# ESP32-C5 register map
Vendor: ESPRESSIF SYSTEMS (SHANGHAI) CO., LTD.; Series: ESP32 C-Series; File version: 1
CPU: RV32IMAC r0p0, little endian, no MPU, no FPU, 0 interrupt priority bits
Address unit: 32 bits
Registers are 32-bit, read-write, reset 0x0 unless marked. A register's access mark holds for its fields unless they carry their own. Offsets are from the block's base; [hi:lo] are bit positions; {n}, {i} and the like mark numbered series.

## AHB_DMA — AHB_DMA Peripheral
Base 0x60080000
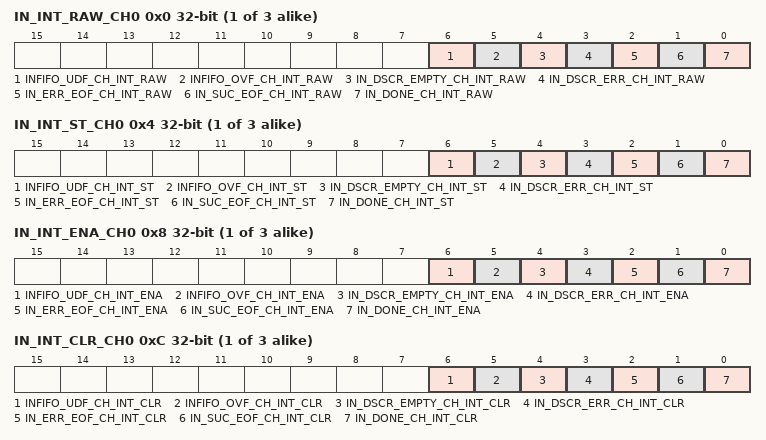
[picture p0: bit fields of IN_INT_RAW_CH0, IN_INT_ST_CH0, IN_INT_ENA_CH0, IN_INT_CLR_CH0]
{0x0+0x10*i} IN_INT_RAW_CH{i} (i=0..2) — Raw interrupt status of RX channel {i}
  [6] INFIFO_UDF_CH_INT_RAW — The raw interrupt status of AHB_DMA_INFIFO_UDF_CH%s_INT.
  [5] INFIFO_OVF_CH_INT_RAW — The raw interrupt status of AHB_DMA_INFIFO_OVF_CH%s_INT.
  [4] IN_DSCR_EMPTY_CH_INT_RAW — The raw interrupt status of AHB_DMA_IN_DSCR_EMPTY_CH%s_INT.
  [3] IN_DSCR_ERR_CH_INT_RAW — The raw interrupt status of AHB_DMA_IN_DSCR_ERR_CH%s_INT.
  [2] IN_ERR_EOF_CH_INT_RAW — The raw interrupt status of AHB_DMA_IN_ERR_EOF_CH%s_INT.
  [1] IN_SUC_EOF_CH_INT_RAW — The raw interrupt status of AHB_DMA_IN_SUC_EOF_CH%s_INT.
  [0] IN_DONE_CH_INT_RAW — The raw interrupt status of AHB_DMA_IN_DONE_CH%s_INT.
{0x4+0x10*i} IN_INT_ST_CH{i} (i=0..2) ro — Masked interrupt status of RX channel {i}
  [6] INFIFO_UDF_CH_INT_ST — The masked interrupt status of AHB_DMA_INFIFO_UDF_CH%s_INT.
  [5] INFIFO_OVF_CH_INT_ST — The masked interrupt status of AHB_DMA_INFIFO_OVF_CH%s_INT.
  [4] IN_DSCR_EMPTY_CH_INT_ST — The masked interrupt status of AHB_DMA_IN_DSCR_EMPTY_CH%s_INT.
  [3] IN_DSCR_ERR_CH_INT_ST — The masked interrupt status of AHB_DMA_IN_DSCR_ERR_CH%s_INT.
  [2] IN_ERR_EOF_CH_INT_ST — The masked interrupt status of AHB_DMA_IN_ERR_EOF_CH%s_INT.
  [1] IN_SUC_EOF_CH_INT_ST — The masked interrupt status of AHB_DMA_IN_SUC_EOF_CH%s_INT.
  [0] IN_DONE_CH_INT_ST — The masked interrupt status of AHB_DMA_IN_DONE_CH%s_INT.
{0x8+0x10*i} IN_INT_ENA_CH{i} (i=0..2) — Interrupt enable bits of RX channel {i}
  [6] INFIFO_UDF_CH_INT_ENA — Write 1 to enable AHB_DMA_INFIFO_UDF_CH%s_INT.
  [5] INFIFO_OVF_CH_INT_ENA — Write 1 to enable AHB_DMA_INFIFO_OVF_CH%s_INT.
  [4] IN_DSCR_EMPTY_CH_INT_ENA — Write 1 to enable AHB_DMA_IN_DSCR_EMPTY_CH%s_INT.
  [3] IN_DSCR_ERR_CH_INT_ENA — Write 1 to enable AHB_DMA_IN_DSCR_ERR_CH%s_INT.
  [2] IN_ERR_EOF_CH_INT_ENA — Write 1 to enable AHB_DMA_IN_ERR_EOF_CH%s_INT.
  [1] IN_SUC_EOF_CH_INT_ENA — Write 1 to enable AHB_DMA_IN_SUC_EOF_CH%s_INT.
  [0] IN_DONE_CH_INT_ENA — Write 1 to enable AHB_DMA_IN_DONE_CH%s_INT.
{0xC+0x10*i} IN_INT_CLR_CH{i} (i=0..2) wo — Interrupt clear bits of RX channel {i}
  [6] INFIFO_UDF_CH_INT_CLR — Write 1 to clear AHB_DMA_INFIFO_UDF_CH%s_INT.
  [5] INFIFO_OVF_CH_INT_CLR — Write 1 to clear AHB_DMA_INFIFO_OVF_CH%s_INT.
  [4] IN_DSCR_EMPTY_CH_INT_CLR — Write 1 to clear AHB_DMA_IN_DSCR_EMPTY_CH%s_INT.
  [3] IN_DSCR_ERR_CH_INT_CLR — Write 1 to clear AHB_DMA_IN_DSCR_ERR_CH%s_INT.
  [2] IN_ERR_EOF_CH_INT_CLR — Write 1 to clear AHB_DMA_IN_ERR_EOF_CH%s_INT.
  [1] IN_SUC_EOF_CH_INT_CLR — Write 1 to clear AHB_DMA_IN_SUC_EOF_CH%s_INT.
  [0] IN_DONE_CH_INT_CLR — Write 1 to clear AHB_DMA_IN_DONE_CH%s_INT.
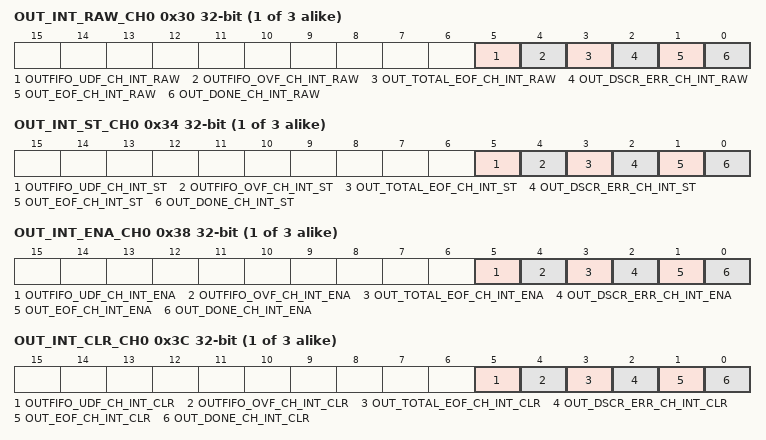
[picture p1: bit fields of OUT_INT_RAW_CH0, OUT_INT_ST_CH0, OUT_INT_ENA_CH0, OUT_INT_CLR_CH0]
{0x30+0x10*i} OUT_INT_RAW_CH{i} (i=0..2) — Raw interrupt status of TX channel {i}
  [5] OUTFIFO_UDF_CH_INT_RAW — The raw interrupt status of AHB_DMA_OUTFIFO_UDF_CH%s_INT.
  [4] OUTFIFO_OVF_CH_INT_RAW — The raw interrupt status of AHB_DMA_OUTFIFO_OVF_CH%s_INT.
  [3] OUT_TOTAL_EOF_CH_INT_RAW — The raw interrupt status of AHB_DMA_OUT_TOTAL_EOF_CH%s_INT.
  [2] OUT_DSCR_ERR_CH_INT_RAW — The raw interrupt status of AHB_DMA_OUT_DSCR_ERR_CH%s_INT.
  [1] OUT_EOF_CH_INT_RAW — The raw interrupt status of AHB_DMA_OUT_EOF_CH%s_INT.
  [0] OUT_DONE_CH_INT_RAW — The raw interrupt status of AHB_DMA_OUT_DONE_CH%s_INT.
{0x34+0x10*i} OUT_INT_ST_CH{i} (i=0..2) ro — Masked interrupt status of TX channel {i}
  [5] OUTFIFO_UDF_CH_INT_ST — The masked interrupt status of AHB_DMA_OUTFIFO_UDF_CH%s_INT.
  [4] OUTFIFO_OVF_CH_INT_ST — The masked interrupt status of AHB_DMA_OUTFIFO_OVF_CH%s_INT.
  [3] OUT_TOTAL_EOF_CH_INT_ST — The masked interrupt status of AHB_DMA_OUT_TOTAL_EOF_CH%s_INT.
  [2] OUT_DSCR_ERR_CH_INT_ST — The masked interrupt status of AHB_DMA_OUT_DSCR_ERR_CH%s_INT.
  [1] OUT_EOF_CH_INT_ST — The masked interrupt status of AHB_DMA_OUT_EOF_CH%s_INT.
  [0] OUT_DONE_CH_INT_ST — The masked interrupt status of AHB_DMA_OUT_DONE_CH%s_INT.
{0x38+0x10*i} OUT_INT_ENA_CH{i} (i=0..2) — Interrupt enable bits of TX channel {i}
  [5] OUTFIFO_UDF_CH_INT_ENA — Write 1 to enable AHB_DMA_OUTFIFO_UDF_CH%s_INT.
  [4] OUTFIFO_OVF_CH_INT_ENA — Write 1 to enable AHB_DMA_OUTFIFO_OVF_CH%s_INT.
  [3] OUT_TOTAL_EOF_CH_INT_ENA — Write 1 to enable AHB_DMA_OUT_TOTAL_EOF_CH%s_INT.
  [2] OUT_DSCR_ERR_CH_INT_ENA — Write 1 to enable AHB_DMA_OUT_DSCR_ERR_CH%s_INT.
  [1] OUT_EOF_CH_INT_ENA — Write 1 to enable AHB_DMA_OUT_EOF_CH%s_INT.
  [0] OUT_DONE_CH_INT_ENA — Write 1 to enable AHB_DMA_OUT_DONE_CH%s_INT.
{0x3C+0x10*i} OUT_INT_CLR_CH{i} (i=0..2) wo — Interrupt clear bits of TX channel {i}
  [5] OUTFIFO_UDF_CH_INT_CLR — Write 1 to clear AHB_DMA_OUTFIFO_UDF_CH%s_INT.
  [4] OUTFIFO_OVF_CH_INT_CLR — Write 1 to clear AHB_DMA_OUTFIFO_OVF_CH%s_INT.
  [3] OUT_TOTAL_EOF_CH_INT_CLR — Write 1 to clear AHB_DMA_OUT_TOTAL_EOF_CH%s_INT.
  [2] OUT_DSCR_ERR_CH_INT_CLR — Write 1 to clear AHB_DMA_OUT_DSCR_ERR_CH%s_INT.
  [1] OUT_EOF_CH_INT_CLR — Write 1 to clear AHB_DMA_OUT_EOF_CH%s_INT.
  [0] OUT_DONE_CH_INT_CLR — Write 1 to clear AHB_DMA_OUT_DONE_CH%s_INT.
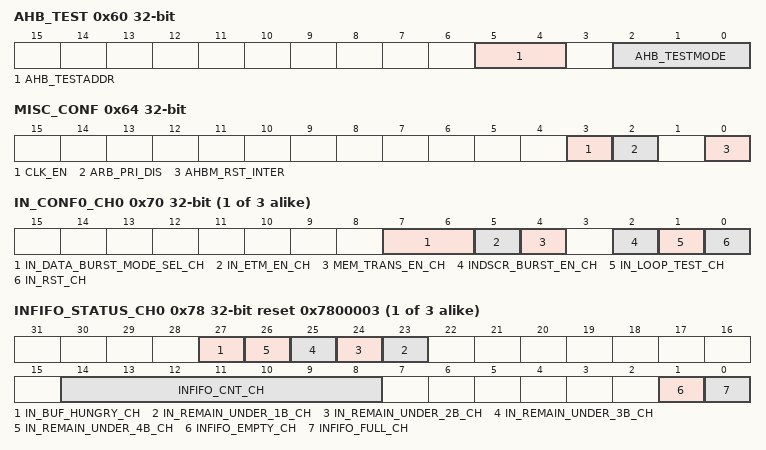
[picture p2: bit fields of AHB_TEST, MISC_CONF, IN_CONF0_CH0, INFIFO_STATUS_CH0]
0x60 AHB_TEST — reserved
  [5:4] AHB_TESTADDR — reserved
  [2:0] AHB_TESTMODE — reserved
0x64 MISC_CONF — Miscellaneous register
  [3] CLK_EN — Configures clock gating.\\0: Support clock only when the application writes registers.\\ 1: Always force the clock on for registers.\\
  [2] ARB_PRI_DIS — Configures whether or not to disable the fixed-priority channel arbitration.\\0: Enable\\1: Disable\\
  [0] AHBM_RST_INTER — Write 1 and then 0 to reset the internal AHB FSM.
0x68 DATE reset 0x2311290 — Version control register
  [31:0] DATE — Version control register.
{0x70+0xC0*i} IN_CONF0_CH{i} (i=0..2) — Configuration register 0 of RX channel {i}
  [7:6] IN_DATA_BURST_MODE_SEL_CH — Configures max burst size for Rx channel%s.\\2'b00: single\\ 2'b01: incr4\\ 2'b10: incr8\\ 2'b11: incr16\\
  [5] IN_ETM_EN_CH — Configures whether or not to enable ETM control for RX channel%s.\\0: Disable\\1: Enable\\
  [4] MEM_TRANS_EN_CH — Configures whether or not to enable memory-to-memory data transfer.\\0: Disable\\1: Enable\\
  [2] INDSCR_BURST_EN_CH — Configures whether or not to enable INCR burst transfer for RX channel %s to read descriptors.\\0: Disable\\1: Enable\\
  [1] IN_LOOP_TEST_CH — Reserved.
  [0] IN_RST_CH — Write 1 and then 0 to reset AHB_DMA channel 0 RX FSM and RX FIFO pointer.
{0x74+0xC0*i} IN_CONF1_CH{i} (i=0..2) — Configuration register 1 of RX channel {i}
  [12] IN_CHECK_OWNER_CH — Configures whether or not to enable owner bit check for RX channel %s.\\0: Disable\\1: Enable\\
{0x78+0xC0*i} INFIFO_STATUS_CH{i} (i=0..2) ro reset 0x7800003 — Receive FIFO status of RX channel {i}
  [27] IN_BUF_HUNGRY_CH — reserved
  [n+22] IN_REMAIN_UNDER_{n}B_CH (n=1..4) — reserved
  [14:8] INFIFO_CNT_CH — Represents the number of data bytes in L1 RX FIFO for RX channel %s.
  [1] INFIFO_EMPTY_CH — Represents whether or not L1 RX FIFO is empty.\\0: Not empty\\1: Empty\\
  [0] INFIFO_FULL_CH — Represents whether or not L1 RX FIFO is full.\\0: Not Full\\1: Full\\
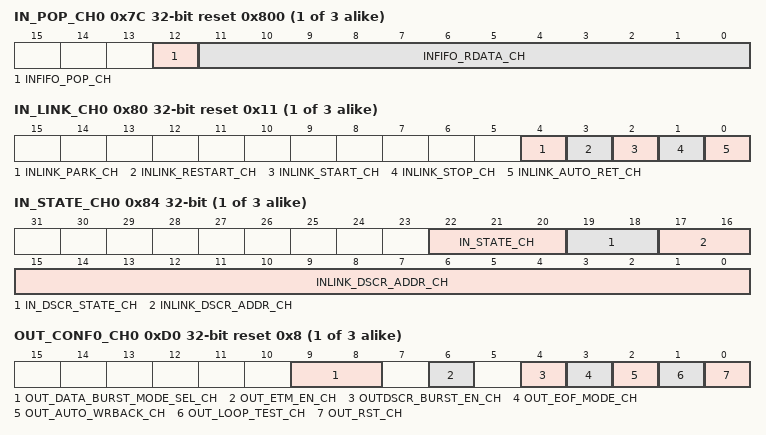
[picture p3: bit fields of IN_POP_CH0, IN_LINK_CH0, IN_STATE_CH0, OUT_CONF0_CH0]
{0x7C+0xC0*i} IN_POP_CH{i} (i=0..2) access per field reset 0x800 — Pop control register of RX channel {i}
  [12] INFIFO_POP_CH wo — Configures whether or not to pop data from AHB_DMA FIFO.\\0: Invalid. No effect\\1: Pop\\
  [11:0] INFIFO_RDATA_CH ro — Represents the data popped from AHB_DMA FIFO.
{0x80+0xC0*i} IN_LINK_CH{i} (i=0..2) access per field reset 0x11 — Linked list descriptor configuration and control register of RX channel {i}
  [4] INLINK_PARK_CH ro — Represents the status of the receive descriptor's FSM.\\0: Running\\1: Idle\\
  [3] INLINK_RESTART_CH wo — Configures whether or not to restart RX channel %s for AHB_DMA transfer.\\0: Invalid. No effect\\1: Restart\\
  [2] INLINK_START_CH wo — Configures whether or not to enable AHB_DMA's RX channel %s for data transfer.\\0: Disable\\1: Enable\\
  [1] INLINK_STOP_CH wo — Configures whether or not to stop AHB_DMA's RX channel %s from receiving data.\\0: Invalid. No effect\\1: Stop\\
  [0] INLINK_AUTO_RET_CH rw — Configures whether or not to return to current receive descriptor's address when there are some errors in current receiving data.\\0: Not return\\1: Return\\
{0x84+0xC0*i} IN_STATE_CH{i} (i=0..2) ro — Receive status of RX channel {i}
  [22:20] IN_STATE_CH — reserved
  [19:18] IN_DSCR_STATE_CH — reserved
  [17:0] INLINK_DSCR_ADDR_CH — Represents the address of the lower 18 bits of the next receive descriptor to be processed.
{0x88+0xC0*i} IN_SUC_EOF_DES_ADDR_CH{i} (i=0..2) ro — Receive descriptor address when EOF occurs on RX channel {i}
  [31:0] IN_SUC_EOF_DES_ADDR_CH — Represents the address of the receive descriptor when the EOF bit in this descriptor is 1.
{0x8C+0xC0*i} IN_ERR_EOF_DES_ADDR_CH{i} (i=0..2) ro — Receive descriptor address when errors occur of RX channel {i}
  [31:0] IN_ERR_EOF_DES_ADDR_CH — Represents the address of the receive descriptor when there are some errors in the currently received data.
{0x90+0xC0*i} IN_DSCR_CH{i} (i=0..2) ro — Current receive descriptor address of RX channel {i}
  [31:0] INLINK_DSCR_CH — Represents the address of the next receive descriptor x+1 pointed by the current receive descriptor that has already been fetched.
{0x94+0xC0*i} IN_DSCR_BF0_CH{i} (i=0..2) ro — The last receive descriptor address of RX channel {i}
  [31:0] INLINK_DSCR_BF0_CH — Represents the address of the current receive descriptor x that has already been fetched.
{0x98+0xC0*i} IN_DSCR_BF1_CH{i} (i=0..2) ro — The second-to-last receive descriptor address of RX channel {i}
  [31:0] INLINK_DSCR_BF1_CH — Represents the address of the previous receive descriptor x-1 that has already been fetched.
{0x9C+0xC0*i} IN_PRI_CH{i} (i=0..2) — Priority register of RX channel {i}
  [3:0] RX_PRI_CH — Configures the priority of RX channel %s.The larger of the value, the higher of the priority.
{0xA0+0xC0*i} IN_PERI_SEL_CH{i} (i=0..2) reset 0x3F — Peripheral selection register of RX channel {i}
  [5:0] PERI_IN_SEL_CH — Configures the peripheral connected to RX channel %s.\\ 0: Dummy\\ 1: SPI2\\ 2: UHCI0\\ 3: I2S0\\ 4: Dummy\\ 5: Dummy\\ 6: AES\\ 7: SHA\\ 8: ADC_DAC\\ 9: PARL_IO\\ 10: Dummy\\ 11~15: Dummy\\
{0xD0+0xC0*i} OUT_CONF0_CH{i} (i=0..2) reset 0x8 — Configuration register 0 of TX channel {i}
  [9:8] OUT_DATA_BURST_MODE_SEL_CH — Configures max burst size for TX channel%s.\\2'b00: single\\ 2'b01: incr4\\ 2'b10: incr8\\ 2'b11: incr16\\
  [6] OUT_ETM_EN_CH — Configures whether or not to enable ETM control for TX channel %s.\\0: Disable\\1: Enable\\
  [4] OUTDSCR_BURST_EN_CH — Configures whether or not to enable INCR burst transfer for TX channel %s reading descriptors.\\0: Disable\\1: Enable\\
  [3] OUT_EOF_MODE_CH — Configures when to generate EOF flag.\\0: EOF flag for TX channel %s is generated when data to be transmitted has been pushed into FIFO in AHB_DMA.\\ 1: EOF flag for TX channel %s is generated when data to be transmitted has been popped from FIFO in AHB_DMA.\\
  [2] OUT_AUTO_WRBACK_CH — Configures whether or not to enable automatic outlink write-back when all the data in TX FIFO has been transmitted.\\0: Disable\\1: Enable\\
  [1] OUT_LOOP_TEST_CH — Reserved.
  [0] OUT_RST_CH — Configures the reset state of AHB_DMA channel %s TX FSM and TX FIFO pointer.\\0: Release reset\\1: Reset\\
{0xD4+0xC0*i} OUT_CONF1_CH{i} (i=0..2) — Configuration register 1 of TX channel {i}
  [12] OUT_CHECK_OWNER_CH — Configures whether or not to enable owner bit check for TX channel %s.\\0: Disable\\1: Enable\\
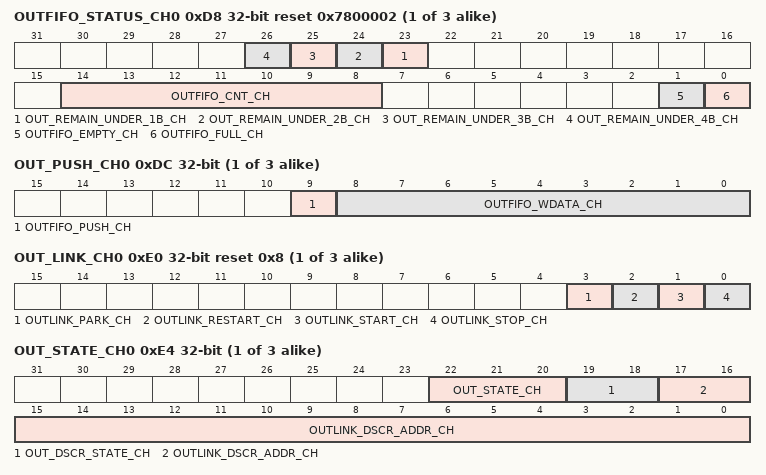
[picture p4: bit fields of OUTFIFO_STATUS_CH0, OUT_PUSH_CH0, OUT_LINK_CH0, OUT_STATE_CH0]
{0xD8+0xC0*i} OUTFIFO_STATUS_CH{i} (i=0..2) ro reset 0x7800002 — Transmit FIFO status of TX channel {i}
  [n+22] OUT_REMAIN_UNDER_{n}B_CH (n=1..4) — Reserved.
  [14:8] OUTFIFO_CNT_CH — Represents the number of data bytes in L1 TX FIFO for TX channel %s.
  [1] OUTFIFO_EMPTY_CH — Represents whether or not L1 TX FIFO is empty.\\0: Not empty\\1: Empty\\
  [0] OUTFIFO_FULL_CH — Represents whether or not L1 TX FIFO is full.\\0: Not Full\\1: Full\\
{0xDC+0xC0*i} OUT_PUSH_CH{i} (i=0..2) access per field — Push control register of TX channel {i}
  [9] OUTFIFO_PUSH_CH wo — Configures whether or not to push data into AHB_DMA FIFO.\\0: Invalid. No effect\\1: Push\\
  [8:0] OUTFIFO_WDATA_CH rw — Configures the data that need to be pushed into AHB_DMA FIFO.
{0xE0+0xC0*i} OUT_LINK_CH{i} (i=0..2) access per field reset 0x8 — Linked list descriptor configuration and control register of TX channel {i}
  [3] OUTLINK_PARK_CH ro — Represents the status of the transmit descriptor's FSM.\\0: Running\\1: Idle\\
  [2] OUTLINK_RESTART_CH wo — Configures whether or not to restart TX channel %s for AHB_DMA transfer.\\0: Invalid. No effect\\1: Restart\\
  [1] OUTLINK_START_CH wo — Configures whether or not to enable AHB_DMA's TX channel %s for data transfer.\\0: Disable\\1: Enable\\
  [0] OUTLINK_STOP_CH wo — Configures whether or not to stop AHB_DMA's TX channel %s from transmitting data.\\0: Invalid. No effect\\1: Stop\\
{0xE4+0xC0*i} OUT_STATE_CH{i} (i=0..2) ro — Transmit status of TX channel {i}
  [22:20] OUT_STATE_CH — reserved
  [19:18] OUT_DSCR_STATE_CH — reserved
  [17:0] OUTLINK_DSCR_ADDR_CH — Represents the lower 18 bits of the address of the next transmit descriptor to be processed.
{0xE8+0xC0*i} OUT_EOF_DES_ADDR_CH{i} (i=0..2) ro — Transmit descriptor address when EOF occurs on TX channel {i}
  [31:0] OUT_EOF_DES_ADDR_CH — Represents the address of the transmit descriptor when the EOF bit in this descriptor is 1.
{0xEC+0xC0*i} OUT_EOF_BFR_DES_ADDR_CH{i} (i=0..2) ro — The last transmit descriptor address when EOF occurs on TX channel {i}
  [31:0] OUT_EOF_BFR_DES_ADDR_CH — Represents the address of the transmit descriptor before the last transmit descriptor.
{0xF0+0xC0*i} OUT_DSCR_CH{i} (i=0..2) ro — Current transmit descriptor address of TX channel {i}
  [31:0] OUTLINK_DSCR_CH — Represents the address of the next transmit descriptor y+1 pointed by the current transmit descriptor that has already been fetched.
{0xF4+0xC0*i} OUT_DSCR_BF0_CH{i} (i=0..2) ro — The last transmit descriptor address of TX channel {i}
  [31:0] OUTLINK_DSCR_BF0_CH — Represents the address of the current transmit descriptor y that has already been fetched.
{0xF8+0xC0*i} OUT_DSCR_BF1_CH{i} (i=0..2) ro — The second-to-last transmit descriptor address of TX channel {i}
  [31:0] OUTLINK_DSCR_BF1_CH — Represents the address of the previous transmit descriptor y-1 that has already been fetched.
{0xFC+0xC0*i} OUT_PRI_CH{i} (i=0..2) — Priority register of TX channel {i}
  [3:0] TX_PRI_CH — Configures the priority of TX channel %s.The larger of the value, the higher of the priority.
{0x100+0xC0*i} OUT_PERI_SEL_CH{i} (i=0..2) reset 0x3F — Peripheral selection register of TX channel {i}
  [5:0] PERI_OUT_SEL_CH — Configures the peripheral connected to TX channel %s.\\ 0: Dummy\\ 1: SPI2\\ 2: UHCI0\\ 3: I2S0\\ 4: Dummy\\ 5: Dummy\\ 6: AES\\ 7: SHA\\ 8: ADC_DAC\\ 9: PARL_IO\\ 10: Dummy\\ 11~15: Dummy\\
{0x2DC+0x28*i} TX_CH_ARB_WEIGHT_CH{i} (i=0..2) — TX channel {i} arbitration weight configuration register
  [3:0] TX_CH_ARB_WEIGHT_CH — Configures the weight(i.e the number of tokens) of TX channel%s
{0x2E0+0x28*i} TX_ARB_WEIGHT_OPT_DIS_CH{i} (i=0..2) — TX channel {i} weight arbitration optimization enable register
  [0] TX_ARB_WEIGHT_OPT_DIS_CH — reserved
{0x354+0x28*i} RX_CH_ARB_WEIGHT_CH{i} (i=0..2) — RX channel {i} arbitration weight configuration register
  [3:0] RX_CH_ARB_WEIGHT_CH — Configures the weight(i.e the number of tokens) of RX channel%s
{0x358+0x28*i} RX_ARB_WEIGHT_OPT_DIS_CH{i} (i=0..2) — RX channel {i} weight arbitration optimization enable register
  [0] RX_ARB_WEIGHT_OPT_DIS_CH — reserved
{0x3AC+4i} IN_LINK_ADDR_CH{i} (i=0..2) — Link list descriptor address configuration of RX channel {i}
  [31:0] INLINK_ADDR_CH — Configures the 32 bits of the first receive descriptor's address.
{0x3B8+4i} OUT_LINK_ADDR_CH{i} (i=0..2) — Link list descriptor address configuration of TX channel {i}
  [31:0] OUTLINK_ADDR_CH — Configures the 32 bits of the first receive descriptor's address.
0x3C4 INTR_MEM_START_ADDR — Accessible address space start address configuration register
  [31:0] ACCESS_INTR_MEM_START_ADDR — Configures the start address of accessible address space.
0x3C8 INTR_MEM_END_ADDR reset 0xFFFFFFFF — Accessible address space end address configuration register
  [31:0] ACCESS_INTR_MEM_END_ADDR — Configures the end address of accessible address space.
0x3DC ARB_TIMEOUT_TX — TX arbitration timeout configuration register
  [15:0] ARB_TIMEOUT_TX — Configures the time slot for TX. Measurement unit: AHB bus clock cycle.
0x400 WEIGHT_EN — TX weight arbitration enable register
  [0] WEIGHT_EN — Configures whether to enable weight arbitration for TX. 0: Disable 1: Enable
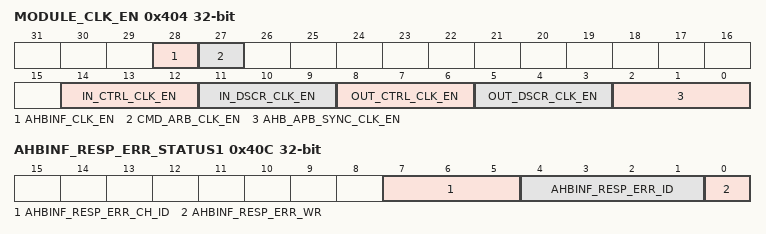
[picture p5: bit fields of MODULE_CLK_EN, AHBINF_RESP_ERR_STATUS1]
0x404 MODULE_CLK_EN — Module clock force on register
  [28] AHBINF_CLK_EN — Configures whether to force on arbinf module clock.
  [27] CMD_ARB_CLK_EN — Configures whether to force on cmd_arb module clock.
  [14:12] IN_CTRL_CLK_EN — Configures whether to force on in_ctrl 2~0 module clock.
  [11:9] IN_DSCR_CLK_EN — Configures whether to force on in_dscr 2~0 module clock.
  [8:6] OUT_CTRL_CLK_EN — Configures whether to force on out_ctrl 2~0 module clock.
  [5:3] OUT_DSCR_CLK_EN — Configures whether to force on out_dscr 2~0 module clock.
  [2:0] AHB_APB_SYNC_CLK_EN — Configures whether to force on ahb_apb_sync 2~0 module clock.
0x408 AHBINF_RESP_ERR_STATUS0 ro — Represents the address of the AHB response error.
  [31:0] ADDR
0x40C AHBINF_RESP_ERR_STATUS1 ro — Represents the AHB response error is write request.
  [7:5] AHBINF_RESP_ERR_CH_ID — Represents the AHB response error request channel id.
  [4:1] AHBINF_RESP_ERR_ID — Represents the AHB response error request id.
  [0] AHBINF_RESP_ERR_WR — Represents the AHB response error is write request.
{0x410+8i} IN_DONE_DES_ADDR_CH{i} (i=0..2) ro — Represents the address of the inlink descriptor when this descriptor is completed.
  [31:0] ADDR
{0x414+8i} OUT_DONE_DES_ADDR_CH{i} (i=0..2) ro — Represents the address of the outlink descriptor when this descriptor is completed.
  [31:0] ADDR

## Notices in the file
Copyright 2025 Espressif Systems (Shanghai) PTE LTD
Licensed under the Apache License, Version 2.0 (the "License");
you may not use this file except in compliance with the License.
You may obtain a copy of the License at
http://www.apache.org/licenses/LICENSE-2.0
Unless required by applicable law or agreed to in writing, software
distributed under the License is distributed on an "AS IS" BASIS,
WITHOUT WARRANTIES OR CONDITIONS OF ANY KIND, either express or implied.
See the License for the specific language governing permissions and
limitations under the License.
